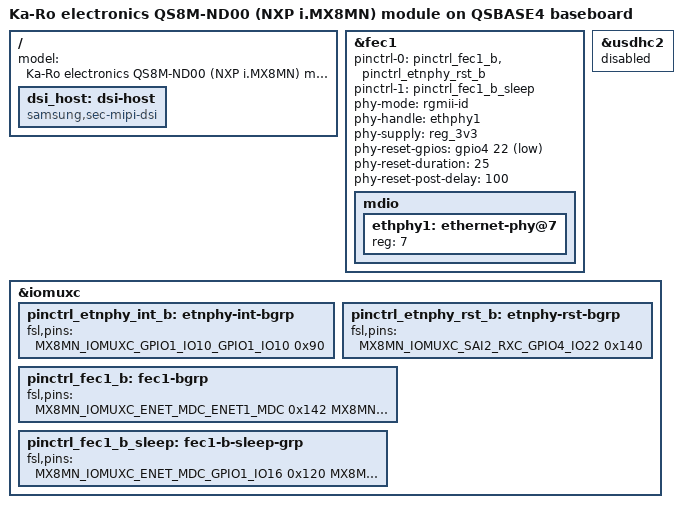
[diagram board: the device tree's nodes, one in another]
// SPDX-License-Identifier: (GPL-2.0 OR MIT)
/*
 * Copyright (C) 2019 Lothar Waßmann <LW@KARO-electronics.de>
 *
 */

/dts-v1/;

#include "imx8mn-qs8m-nd00.dts"

/ {
	model = "Ka-Ro electronics QS8M-ND00 (NXP i.MX8MN) module on QSBASE4 baseboard";

	dsi_host: dsi-host {
		compatible = "samsung,sec-mipi-dsi";
		status = "okay";
	};
};

&fec1 {
	pinctrl-names = "default", "sleep";
	pinctrl-0 = <&pinctrl_fec1_b &pinctrl_etnphy_rst_b>;
	pinctrl-1 = <&pinctrl_fec1_b_sleep>;
	phy-mode = "rgmii-id";
	phy-handle = <&ethphy1>;
	phy-supply = <&reg_3v3>;
	phy-reset-gpios = <&gpio4 22 GPIO_ACTIVE_LOW>;
	phy-reset-duration = <25>;
	phy-reset-post-delay = <100>;
	status = "okay";

	mdio {
		#address-cells = <1>;
		#size-cells = <0>;

		ethphy1: ethernet-phy@7 {
			reg = <7>;
		};
	};
};

&usdhc2 {
	status = "disabled";
};

&iomuxc {
	pinctrl_etnphy_int_b: etnphy-int-bgrp {
		fsl,pins = <
			    MX8MN_IOMUXC_GPIO1_IO10_GPIO1_IO10		0x90
		>;
	};

	pinctrl_etnphy_rst_b: etnphy-rst-bgrp {
		fsl,pins = <
			    MX8MN_IOMUXC_SAI2_RXC_GPIO4_IO22		0x140
		>;
	};

	pinctrl_fec1_b: fec1-bgrp {
		fsl,pins = <
			    MX8MN_IOMUXC_ENET_MDC_ENET1_MDC		0x142
			    MX8MN_IOMUXC_ENET_MDIO_ENET1_MDIO		0x142
			    MX8MN_IOMUXC_ENET_TXC_ENET1_RGMII_TXC	0x010
			    MX8MN_IOMUXC_ENET_TD0_ENET1_RGMII_TD0	0x016
			    MX8MN_IOMUXC_ENET_TD1_ENET1_RGMII_TD1	0x016
			    MX8MN_IOMUXC_ENET_TD2_ENET1_RGMII_TD2	0x016
			    MX8MN_IOMUXC_ENET_TD3_ENET1_RGMII_TD3	0x016
			    MX8MN_IOMUXC_ENET_RD0_ENET1_RGMII_RD0	0x110 /* MODE0 */
			    MX8MN_IOMUXC_ENET_RD1_ENET1_RGMII_RD1	0x150 /* MODE1 */
			    MX8MN_IOMUXC_ENET_RD2_ENET1_RGMII_RD2	0x150 /* MODE2 */
			    MX8MN_IOMUXC_ENET_RD3_ENET1_RGMII_RD3	0x150 /* MODE3 */
			    MX8MN_IOMUXC_ENET_RXC_ENET1_RGMII_RXC	0x156 /* PHYAD2 */
			    MX8MN_IOMUXC_ENET_RX_CTL_ENET1_RGMII_RX_CTL	0x156 /* CLK125_EN */
			    MX8MN_IOMUXC_ENET_TX_CTL_ENET1_RGMII_TX_CTL	0x016 /* LED_MODE */
		>;
	};

	pinctrl_fec1_b_sleep: fec1-b-sleep-grp {
		fsl,pins = <
			    MX8MN_IOMUXC_ENET_MDC_GPIO1_IO16		0x120
			    MX8MN_IOMUXC_ENET_MDIO_GPIO1_IO17		0x120
			    MX8MN_IOMUXC_ENET_TXC_GPIO1_IO23		0x120
			    MX8MN_IOMUXC_ENET_TD0_GPIO1_IO21		0x120
			    MX8MN_IOMUXC_ENET_TD1_GPIO1_IO20		0x120
			    MX8MN_IOMUXC_ENET_TD2_GPIO1_IO19		0x120
			    MX8MN_IOMUXC_ENET_TD3_GPIO1_IO18		0x120
			    MX8MN_IOMUXC_ENET_RD0_GPIO1_IO26		0x120
			    MX8MN_IOMUXC_ENET_RD1_GPIO1_IO27		0x120
			    MX8MN_IOMUXC_ENET_RD2_GPIO1_IO28		0x120
			    MX8MN_IOMUXC_ENET_RD3_GPIO1_IO29		0x120
			    MX8MN_IOMUXC_ENET_RXC_GPIO1_IO25		0x120
			    MX8MN_IOMUXC_ENET_RX_CTL_GPIO1_IO24		0x120
			    MX8MN_IOMUXC_ENET_TX_CTL_GPIO1_IO22		0x120
		>;
	};
};
